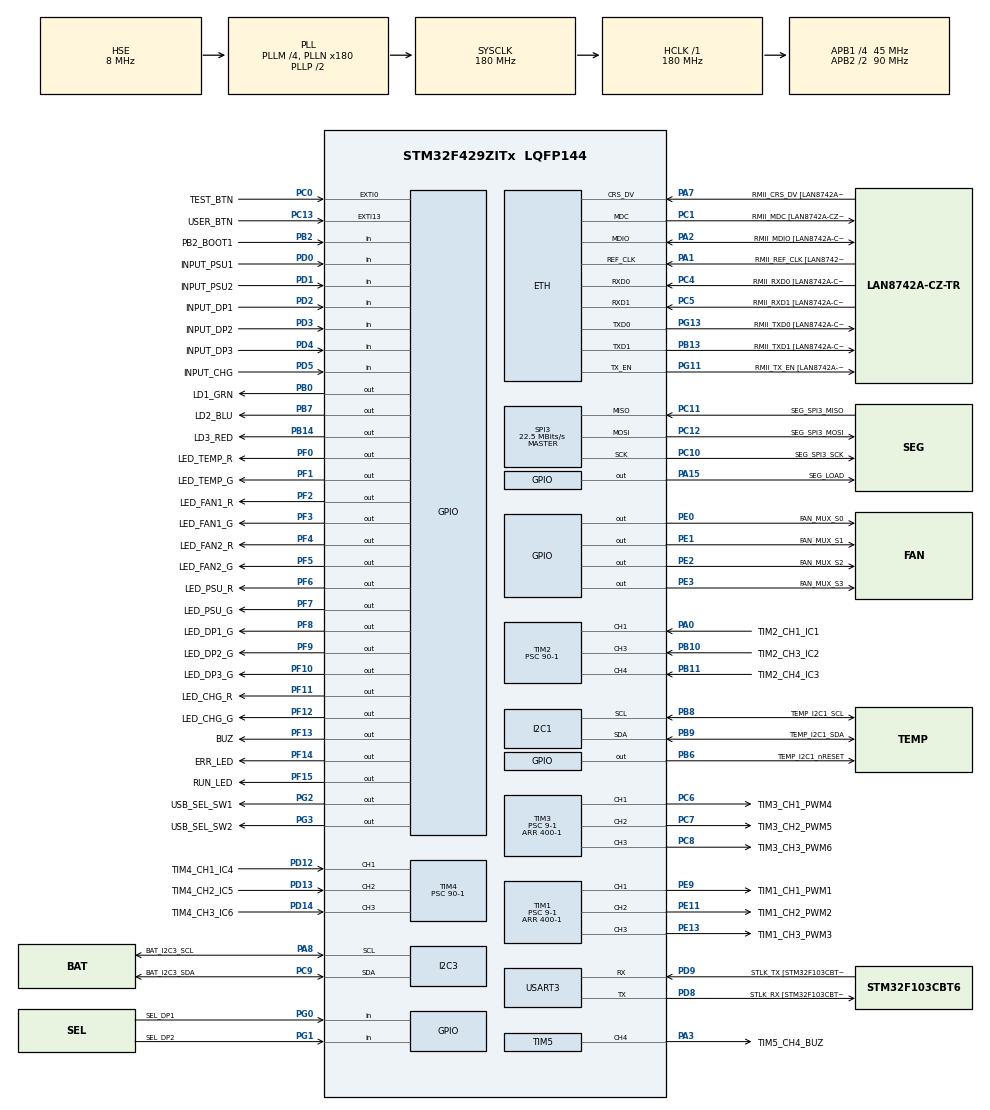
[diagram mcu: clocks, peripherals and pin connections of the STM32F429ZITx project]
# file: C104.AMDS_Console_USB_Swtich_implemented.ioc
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ETH.MediaInterface=HAL_ETH_RMII_MODE
LWIP.BSP.number=1
LWIP.GATEWAY_ADDRESS=192.168.050.001
LWIP.IP_ADDRESS=192.168.050.100
LWIP.LWIP_DHCP=0
LWIP.NETMASK_ADDRESS=255.255.255.000
LWIP.Version=v2.1.2_Cube
LWIP0.BSP.STBoard=false
LWIP0.BSP.api=BSP_COMPONENT_DRIVER
LWIP0.BSP.component=LAN8742
LWIP0.BSP.instance=LAN8742
LWIP0.BSP.name=Driver_PHY
LWIP0.BSP.semaphore=S_LAN8742
LWIP0.BSP.solution=LAN8742
Mcu.Family=STM32F4
Mcu.Name=STM32F429ZITx
Mcu.Package=LQFP144
NVIC.ETH_IRQn=true\:0\:0\:false\:false\:true\:true\:true\:true
NVIC.EXTI0_IRQn=true\:3\:0\:true\:false\:true\:true\:true\:true
NVIC.EXTI15_10_IRQn=true\:0\:0\:false\:false\:true\:true\:true\:true
NVIC.PriorityGroup=NVIC_PRIORITYGROUP_4
NVIC.TIM2_IRQn=true\:0\:0\:true\:false\:true\:true\:true\:true
NVIC.TIM4_IRQn=true\:0\:0\:true\:false\:true\:true\:true\:true
NVIC.TIM6_DAC_IRQn=true\:1\:0\:true\:false\:true\:true\:true\:true
NVIC.USART3_IRQn=true\:0\:0\:false\:false\:true\:true\:true\:true
PA0/WKUP.GPIO_Label=TIM2_CH1_IC1
PA0/WKUP.Signal=S_TIM2_CH1_ETR
PA1.GPIO_Label=RMII_REF_CLK [LAN8742A-CZ-TR_REFCLK0]
PA1.Mode=RMII
PA1.Signal=ETH_REF_CLK
PA13.GPIO_Label=SWDIO
PA13.Mode=Serial_Wire
PA13.Signal=SYS_JTMS-SWDIO
PA14.GPIO_Label=SWCLK
PA14.Mode=Serial_Wire
PA14.Signal=SYS_JTCK-SWCLK
PA15.GPIO_Label=SEG_LOAD
PA15.Signal=GPIO_Output
PA2.GPIO_Label=RMII_MDIO [LAN8742A-CZ-TR_MDIO]
PA2.Mode=RMII
PA2.Signal=ETH_MDIO
PA3.GPIO_Label=TIM5_CH4_BUZ
PA3.Signal=S_TIM5_CH4
PA7.GPIO_Label=RMII_CRS_DV [LAN8742A-CZ-TR_CRS_DV]
PA7.Mode=RMII
PA7.Signal=ETH_CRS_DV
PA8.GPIO_Label=BAT_I2C3_SCL
PA8.Mode=I2C
PA8.Signal=I2C3_SCL
PB0.GPIO_Label=LD1_GRN
PB0.Signal=GPIO_Output
PB10.GPIO_Label=TIM2_CH3_IC2
PB10.Signal=S_TIM2_CH3
PB11.GPIO_Label=TIM2_CH4_IC3
PB11.Signal=S_TIM2_CH4
PB13.GPIO_Label=RMII_TXD1 [LAN8742A-CZ-TR_TXD1]
PB13.Mode=RMII
PB13.Signal=ETH_TXD1
PB14.GPIO_Label=LD3_RED
PB14.Signal=GPIO_Output
PB2/BOOT1.GPIO_Label=PB2_BOOT1
PB2/BOOT1.Signal=GPIO_Input
PB6.GPIO_Label=TEMP_I2C1_nRESET
PB6.Signal=GPIO_Output
PB7.GPIO_Label=LD2_BLU
PB7.Signal=GPIO_Output
PB8.GPIO_Label=TEMP_I2C1_SCL
PB8.Mode=I2C
PB8.Signal=I2C1_SCL
PB9.GPIO_Label=TEMP_I2C1_SDA
PB9.Mode=I2C
PB9.Signal=I2C1_SDA
PC0.GPIO_Label=TEST_BTN
PC0.GPIO_ModeDefaultEXTI=GPIO_MODE_IT_FALLING
PC0.GPIO_PuPd=GPIO_NOPULL
PC0.Signal=GPXTI0
PC1.GPIO_Label=RMII_MDC [LAN8742A-CZ-TR_MDC]
PC1.Mode=RMII
PC1.Signal=ETH_MDC
PC10.GPIO_Label=SEG_SPI3_SCK
PC10.Mode=Full_Duplex_Master
PC10.Signal=SPI3_SCK
PC11.GPIO_Label=SEG_SPI3_MISO
PC11.Mode=Full_Duplex_Master
PC11.Signal=SPI3_MISO
PC12.GPIO_Label=SEG_SPI3_MOSI
PC12.Mode=Full_Duplex_Master
PC12.Signal=SPI3_MOSI
PC13.GPIO_Label=USER_BTN
PC13.GPIO_ModeDefaultEXTI=GPIO_MODE_IT_FALLING
PC13.GPIO_PuPd=GPIO_NOPULL
PC13.Signal=GPXTI13
PC14/OSC32_IN.Mode=LSE-External-Oscillator
PC14/OSC32_IN.Signal=RCC_OSC32_IN
PC15/OSC32_OUT.Mode=LSE-External-Oscillator
PC15/OSC32_OUT.Signal=RCC_OSC32_OUT
PC4.GPIO_Label=RMII_RXD0 [LAN8742A-CZ-TR_RXD0]
PC4.Mode=RMII
PC4.Signal=ETH_RXD0
PC5.GPIO_Label=RMII_RXD1 [LAN8742A-CZ-TR_RXD1]
PC5.Mode=RMII
PC5.Signal=ETH_RXD1
PC6.GPIO_Label=TIM3_CH1_PWM4
PC6.Signal=S_TIM3_CH1
PC7.GPIO_Label=TIM3_CH2_PWM5
PC7.Signal=S_TIM3_CH2
PC8.GPIO_Label=TIM3_CH3_PWM6
PC8.Signal=S_TIM3_CH3
PC9.GPIO_Label=BAT_I2C3_SDA
PC9.Mode=I2C
PC9.Signal=I2C3_SDA
PD0.GPIO_Label=INPUT_PSU1
PD0.GPIO_PuPd=GPIO_PULLUP
PD0.Signal=GPIO_Input
PD1.GPIO_Label=INPUT_PSU2
PD1.GPIO_PuPd=GPIO_PULLUP
PD1.Signal=GPIO_Input
PD12.GPIO_Label=TIM4_CH1_IC4
PD12.Signal=S_TIM4_CH1
PD13.GPIO_Label=TIM4_CH2_IC5
PD13.Signal=S_TIM4_CH2
PD14.GPIO_Label=TIM4_CH3_IC6
PD14.Signal=S_TIM4_CH3
PD2.GPIO_Label=INPUT_DP1
PD2.GPIO_PuPd=GPIO_PULLDOWN
PD2.Signal=GPIO_Input
PD3.GPIO_Label=INPUT_DP2
PD3.GPIO_PuPd=GPIO_PULLDOWN
PD3.Signal=GPIO_Input
PD4.GPIO_Label=INPUT_DP3
PD4.GPIO_PuPd=GPIO_PULLUP
PD4.Signal=GPIO_Input
PD5.GPIO_Label=INPUT_CHG
PD5.GPIO_PuPd=GPIO_PULLUP
PD5.Signal=GPIO_Input
PD8.GPIO_Label=STLK_RX [STM32F103CBT6_PA3]
PD8.Mode=Asynchronous
PD8.Signal=USART3_TX
PD9.GPIO_Label=STLK_TX [STM32F103CBT6_PA2]
PD9.Mode=Asynchronous
PD9.Signal=USART3_RX
PE0.GPIO_Label=FAN_MUX_S0
PE0.Signal=GPIO_Output
PE1.GPIO_Label=FAN_MUX_S1
PE1.Signal=GPIO_Output
PE11.GPIO_Label=TIM1_CH2_PWM2
PE11.Signal=S_TIM1_CH2
PE13.GPIO_Label=TIM1_CH3_PWM3
PE13.Signal=S_TIM1_CH3
PE2.GPIO_Label=FAN_MUX_S2
PE2.Signal=GPIO_Output
PE3.GPIO_Label=FAN_MUX_S3
PE3.Signal=GPIO_Output
PE9.GPIO_Label=TIM1_CH1_PWM1
PE9.Signal=S_TIM1_CH1
PF0.GPIO_Label=LED_TEMP_R
PF0.PinState=GPIO_PIN_SET
PF0.Signal=GPIO_Output
PF1.GPIO_Label=LED_TEMP_G
PF1.PinState=GPIO_PIN_SET
PF1.Signal=GPIO_Output
PF10.GPIO_Label=LED_DP3_G
PF10.PinState=GPIO_PIN_SET
PF10.Signal=GPIO_Output
PF11.GPIO_Label=LED_CHG_R
PF11.PinState=GPIO_PIN_SET
PF11.Signal=GPIO_Output
PF12.GPIO_Label=LED_CHG_G
PF12.PinState=GPIO_PIN_SET
PF12.Signal=GPIO_Output
PF13.GPIO_Label=BUZ
PF13.PinState=GPIO_PIN_SET
PF13.Signal=GPIO_Output
PF14.GPIO_Label=ERR_LED
PF14.Signal=GPIO_Output
PF15.GPIO_Label=RUN_LED
PF15.Signal=GPIO_Output
PF2.GPIO_Label=LED_FAN1_R
PF2.PinState=GPIO_PIN_SET
PF2.Signal=GPIO_Output
PF3.GPIO_Label=LED_FAN1_G
PF3.PinState=GPIO_PIN_SET
PF3.Signal=GPIO_Output
PF4.GPIO_Label=LED_FAN2_R
PF4.PinState=GPIO_PIN_SET
PF4.Signal=GPIO_Output
PF5.GPIO_Label=LED_FAN2_G
PF5.PinState=GPIO_PIN_SET
PF5.Signal=GPIO_Output
PF6.GPIO_Label=LED_PSU_R
PF6.PinState=GPIO_PIN_SET
PF6.Signal=GPIO_Output
PF7.GPIO_Label=LED_PSU_G
PF7.PinState=GPIO_PIN_SET
PF7.Signal=GPIO_Output
PF8.GPIO_Label=LED_DP1_G
PF8.PinState=GPIO_PIN_SET
PF8.Signal=GPIO_Output
PF9.GPIO_Label=LED_DP2_G
PF9.PinState=GPIO_PIN_SET
PF9.Signal=GPIO_Output
PG0.GPIO_Label=SEL_DP1
PG0.Signal=GPIO_Input
PG1.GPIO_Label=SEL_DP2
PG1.Signal=GPIO_Input
PG11.GPIO_Label=RMII_TX_EN [LAN8742A-CZ-TR_TXEN]
PG11.Mode=RMII
PG11.Signal=ETH_TX_EN
PG13.GPIO_Label=RMII_TXD0 [LAN8742A-CZ-TR_TXD0]
PG13.Mode=RMII
PG13.Signal=ETH_TXD0
PG2.GPIO_Label=USB_SEL_SW1
PG2.Signal=GPIO_Output
PG3.GPIO_Label=USB_SEL_SW2
PG3.Signal=GPIO_Output
PH0/OSC_IN.Mode=HSE-External-Oscillator
PH0/OSC_IN.Signal=RCC_OSC_IN
PH1/OSC_OUT.Mode=HSE-External-Oscillator
PH1/OSC_OUT.Signal=RCC_OSC_OUT
ProjectManager.HeapSize=0x200
ProjectManager.StackSize=0x400
ProjectManager.TargetToolchain=STM32CubeIDE
RCC.48MHZClocksFreq_Value=51428571.428571425
RCC.AHBFreq_Value=180000000
RCC.APB1CLKDivider=RCC_HCLK_DIV4
RCC.APB1Freq_Value=45000000
RCC.APB1TimFreq_Value=90000000
RCC.APB2CLKDivider=RCC_HCLK_DIV2
RCC.APB2Freq_Value=90000000
RCC.APB2TimFreq_Value=180000000
RCC.CortexFreq_Value=180000000
RCC.HCLKFreq_Value=180000000
RCC.HSE_VALUE=8000000
RCC.HSI_VALUE=16000000
RCC.PLLM=4
RCC.PLLMUL=RCC_PLL_MUL9
RCC.PLLN=180
RCC.PLLQ=7
RCC.PLLSourceVirtual=RCC_PLLSOURCE_HSE
RCC.PRESCALERUSB=RCC_USBCLKSOURCE_PLL_DIV1_5
RCC.SYSCLKFreq_VALUE=180000000
RCC.SYSCLKSource=RCC_SYSCLKSOURCE_PLLCLK
RCC.SYSCLKSourceVirtual=RCC_SYSCLKSOURCE_PLLCLK
RCC.USBFreq_Value=48000000
RCC.VCOOutputFreq_Value=360000000
SH.S_TIM1_CH1.0=TIM1_CH1,PWM Generation1 CH1
SH.S_TIM1_CH2.0=TIM1_CH2,PWM Generation2 CH2
SH.S_TIM1_CH3.0=TIM1_CH3,PWM Generation3 CH3
SH.S_TIM2_CH1_ETR.0=TIM2_CH1,Input_Capture1_from_TI1
SH.S_TIM2_CH3.0=TIM2_CH3,Input_Capture3_from_TI3
SH.S_TIM2_CH4.0=TIM2_CH4,Input_Capture4_from_TI4
SH.S_TIM3_CH1.0=TIM3_CH1,PWM Generation1 CH1
SH.S_TIM3_CH2.0=TIM3_CH2,PWM Generation2 CH2
SH.S_TIM3_CH3.0=TIM3_CH3,PWM Generation3 CH3
SH.S_TIM4_CH1.0=TIM4_CH1,Input_Capture1_from_TI1
SH.S_TIM4_CH2.0=TIM4_CH2,Input_Capture2_from_TI2
SH.S_TIM4_CH3.0=TIM4_CH3,Input_Capture3_from_TI3
SH.S_TIM5_CH4.0=TIM5_CH4,PWM Generation4 CH4
SPI3.BaudRatePrescaler=SPI_BAUDRATEPRESCALER_2
SPI3.CalculateBaudRate=22.5 MBits/s
SPI3.Direction=SPI_DIRECTION_2LINES
SPI3.Mode=SPI_MODE_MASTER
SPI3.VirtualType=VM_MASTER
TIM1.Channel-PWM\ Generation1\ CH1=TIM_CHANNEL_1
TIM1.Channel-PWM\ Generation2\ CH2=TIM_CHANNEL_2
TIM1.Channel-PWM\ Generation3\ CH3=TIM_CHANNEL_3
TIM1.Period=400-1
TIM1.Prescaler=9-1
TIM2.Channel-Input_Capture1_from_TI1=TIM_CHANNEL_1
TIM2.Channel-Input_Capture3_from_TI3=TIM_CHANNEL_3
TIM2.Channel-Input_Capture4_from_TI4=TIM_CHANNEL_4
TIM2.ICFilter_CH1=15
TIM2.ICFilter_CH3=15
TIM2.ICFilter_CH4=15
TIM2.Prescaler=90-1
TIM3.Channel-PWM\ Generation1\ CH1=TIM_CHANNEL_1
TIM3.Channel-PWM\ Generation2\ CH2=TIM_CHANNEL_2
TIM3.Channel-PWM\ Generation3\ CH3=TIM_CHANNEL_3
TIM3.Period=400-1
TIM3.Prescaler=9-1
TIM4.Channel-Input_Capture1_from_TI1=TIM_CHANNEL_1
TIM4.Channel-Input_Capture2_from_TI2=TIM_CHANNEL_2
TIM4.Channel-Input_Capture3_from_TI3=TIM_CHANNEL_3
TIM4.ICFilter_CH1=15
TIM4.ICFilter_CH2=15
TIM4.ICFilter_CH3=15
TIM4.Prescaler=90-1
TIM5.Channel-PWM\ Generation4\ CH4=TIM_CHANNEL_4
TIM5.Period=370
TIM5.Prescaler=90-1
TIM5.Pulse-PWM\ Generation4\ CH4=185
TIM6.Period=10000-1
TIM6.Prescaler=900-1
USART3.VirtualMode=VM_ASYNC
VP_LWIP_VS_Enabled.Mode=Enabled
VP_TIM6_VS_ClockSourceINT.Mode=Enable_Timer
board=NUCLEO-F429ZI

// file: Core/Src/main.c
/* USER CODE BEGIN Header */
/**
  ******************************************************************************
  * @file           : main.c
  * @brief          : Main program body
  ******************************************************************************
  * @attention
  *
  * Copyright (c) 2024 STMicroelectronics.
  * All rights reserved.
  *
  * This software is licensed under terms that can be found in the LICENSE file
  * in the root directory of this software component.
  * If no LICENSE file comes with this software, it is provided AS-IS.
  *
  ******************************************************************************
  */
/* USER CODE END Header */
#include "main.h"
#include "i2c.h"
#include "lwip.h"
#include "spi.h"
#include "tim.h"
#include "usart.h"
#include "gpio.h"

/* USER CODE BEGIN Includes */
#include <stdlib.h>
#include <udp_server.h>
#include "ring_buffer.h"
#include "pid.h"
#include "ema.h"
#include "user_timer.h"
#include "fan_control.h"
#include "debug_uart.h"
#include "hih8131.h"
#include "bq34z100.h"
#include "process.h"
#include "max7219.h"
#include "display.h"
#include "udp_protocol.h"
#include "send.h"
#include "debug_uart.h"
#include "buzzer.h"

/* USER CODE END Includes */

/* USER CODE BEGIN PV */
uint8_t timer_interrupt_100ms_done = 0;
uint8_t timer_interrupt_1sec_done = 0;
uint8_t key_pressed = 0;
uint8_t keyno = 0;

//----------------------
//RingBuffer rxBuffer;

/* USER CODE END PV */

void SystemClock_Config(void);
/* USER CODE BEGIN PFP */
int _write(int file, char* p, int len)
{
	HAL_UART_Transmit(&huart3, (const uint8_t *)p, len, 10);
	return len;
}

/* USER CODE END PFP */

/* USER CODE BEGIN 0 */
uint32_t stamp_100ms = 0;
uint32_t stamp_1sec = 0;
int8_t cmd_received = 1;
//uint8_t command[50] = {0, };

//UDP Server
extern struct netif gnetif;
extern ip4_addr_t ipaddr;

/* USER CODE END 0 */

int main(void)
{

  /* MCU Configuration--------------------------------------------------------*/

  /* Reset of all peripherals, Initializes the Flash interface and the Systick. */
  HAL_Init();

  /* Configure the system clock */
  SystemClock_Config();

  /* Initialize all configured peripherals */
  MX_GPIO_Init();
  MX_USART3_UART_Init();
  MX_I2C1_Init();
  MX_TIM1_Init();
  MX_TIM2_Init();
  MX_TIM3_Init();
  MX_TIM4_Init();
  MX_LWIP_Init();
  MX_TIM6_Init();
  MX_I2C3_Init();
  MX_SPI3_Init();
  MX_TIM5_Init();
  /* USER CODE BEGIN 2 */
  uTimer_Init();
  LED_Init();
  MAX7219_Init();
  Buzzer_Init();

  DBG_Uart_Init();
  HAL_UART_Receive_IT(&huart3, (uint8_t *)&rxBuffer.buffer[rxBuffer.head], 1);

  FAN_Init();
  HMTP_Init();
  UDP_Protocol_Init();

  configure_mac_filter();
  udpServer_init();
  Process_Init();

  HAL_TIM_Base_Start_IT(&htim6);

 printf("\nC104.AMDS_Console_TempStatus_with_avg_value\n");

 //Send_Portable_Status()
 setbuf(stdout,NULL);
  /* USER CODE END 2 */

  /* Infinite loop */
  /* USER CODE BEGIN WHILE */
 HAL_GPIO_WritePin(LED_DP1_G_GPIO_Port, LED_DP1_G_Pin, GPIO_PIN_SET);
 HAL_GPIO_WritePin(LED_DP2_G_GPIO_Port, LED_DP2_G_Pin, GPIO_PIN_SET);
 HAL_GPIO_WritePin(LED_DP3_G_GPIO_Port, LED_DP3_G_Pin, GPIO_PIN_SET);

 uint8_t toggle = 0;
  while (1)
  {
	//HAL_GPIO_WritePin(LED_DP1_G_GPIO_Port, LED_DP1_G_Pin, GPIO_PIN_RESET);
    ethernetif_input(&gnetif);
    sys_check_timeouts();

    HAL_GPIO_WritePin(LED_DP1_G_GPIO_Port, LED_DP1_G_Pin, GPIO_PIN_SET);
    HAL_GPIO_WritePin(LED_DP2_G_GPIO_Port, LED_DP2_G_Pin, GPIO_PIN_SET);
    HAL_GPIO_WritePin(LED_DP3_G_GPIO_Port, LED_DP3_G_Pin, GPIO_PIN_SET);

    Process_Console_Status();

    if(key_pressed == 1)
    {
      toggle = !toggle;

      if(uTimer_CheckTimeOut((uint8_t)uTimerDebounce) == TRUE)
      {
        //if(toggle==1) Buzzer_On();
        //else Buzzer_Off();

        //Send_Portable_Status();
        key_pressed = 0;
      }
    }

    /* USER CODE END WHILE */

  }
}

void SystemClock_Config(void)
{
  RCC_OscInitTypeDef RCC_OscInitStruct = {0};
  RCC_ClkInitTypeDef RCC_ClkInitStruct = {0};

  /** Configure the main internal regulator output voltage
  */
  __HAL_RCC_PWR_CLK_ENABLE();
  __HAL_PWR_VOLTAGESCALING_CONFIG(PWR_REGULATOR_VOLTAGE_SCALE1);

  /** Initializes the RCC Oscillators according to the specified parameters
  * in the RCC_OscInitTypeDef structure.
  */
  RCC_OscInitStruct.OscillatorType = RCC_OSCILLATORTYPE_HSE;
  RCC_OscInitStruct.HSEState = RCC_HSE_ON;
  RCC_OscInitStruct.PLL.PLLState = RCC_PLL_ON;
  RCC_OscInitStruct.PLL.PLLSource = RCC_PLLSOURCE_HSE;
  RCC_OscInitStruct.PLL.PLLM = 4;
  RCC_OscInitStruct.PLL.PLLN = 180;
  RCC_OscInitStruct.PLL.PLLP = RCC_PLLP_DIV2;
  RCC_OscInitStruct.PLL.PLLQ = 7;
  if (HAL_RCC_OscConfig(&RCC_OscInitStruct) != HAL_OK)
  {
    Error_Handler();
  }

  /** Activate the Over-Drive mode
  */
  if (HAL_PWREx_EnableOverDrive() != HAL_OK)
  {
    Error_Handler();
  }

  /** Initializes the CPU, AHB and APB buses clocks
  */
  RCC_ClkInitStruct.ClockType = RCC_CLOCKTYPE_HCLK|RCC_CLOCKTYPE_SYSCLK
                              |RCC_CLOCKTYPE_PCLK1|RCC_CLOCKTYPE_PCLK2;
  RCC_ClkInitStruct.SYSCLKSource = RCC_SYSCLKSOURCE_PLLCLK;
  RCC_ClkInitStruct.AHBCLKDivider = RCC_SYSCLK_DIV1;
  RCC_ClkInitStruct.APB1CLKDivider = RCC_HCLK_DIV4;
  RCC_ClkInitStruct.APB2CLKDivider = RCC_HCLK_DIV2;

  if (HAL_RCC_ClockConfig(&RCC_ClkInitStruct, FLASH_LATENCY_5) != HAL_OK)
  {
    Error_Handler();
  }
}

/* USER CODE BEGIN 4 */
void HAL_TIM_PeriodElapsedCallback(TIM_HandleTypeDef *htim)
{
	static uint32_t last_blink_tick = 0;

	if(htim->Instance == TIM6)
	{
		if (HAL_GetTick() - last_blink_tick >= 500) {
			last_blink_tick = HAL_GetTick();

			HAL_GPIO_TogglePin(RUN_LED_GPIO_Port, RUN_LED_Pin);
			HAL_GPIO_TogglePin(LD3_RED_GPIO_Port, LD3_RED_Pin);
			HAL_GPIO_TogglePin(LD2_BLU_GPIO_Port, LD2_BLU_Pin);

			HAL_GPIO_TogglePin(LED_DP1_G_GPIO_Port, LED_DP1_G_Pin);
			HAL_GPIO_TogglePin(LED_DP2_G_GPIO_Port, LED_DP2_G_Pin);
			HAL_GPIO_TogglePin(LED_DP3_G_GPIO_Port, LED_DP3_G_Pin);

			//HAL_GPIO_TogglePin(LED_TEMP_R_GPIO_Port, LED_TEMP_R_Pin);
			//HAL_GPIO_TogglePin(LED_TEMP_G_GPIO_Port, LED_TEMP_G_Pin);
			//HAL_GPIO_TogglePin(LED_TEMP_R_GPIO_Port, LED_TEMP_R_Pin);
			//HAL_GPIO_TogglePin(LED_TEMP_G_GPIO_Port, LED_TEMP_G_Pin);

			//HAL_GPIO_TogglePin(LED_PSU_R_GPIO_Port, LED_PSU_R_Pin);
			//HAL_GPIO_TogglePin(LED_PSU_G_GPIO_Port, LED_PSU_G_Pin);

			//HAL_GPIO_TogglePin(LED_FAN1_R_GPIO_Port, LED_FAN1_R_Pin);
			//HAL_GPIO_TogglePin(LED_FAN1_G_GPIO_Port, LED_FAN1_G_Pin);

			//HAL_GPIO_TogglePin(LED_FAN2_R_GPIO_Port, LED_FAN2_R_Pin);
			//HAL_GPIO_TogglePin(LED_FAN2_G_GPIO_Port, LED_FAN2_G_Pin);
		}
	}
}

void HAL_GPIO_EXTI_Callback(uint16_t GPIO_Pin)
{
    if(GPIO_Pin == USER_BTN_Pin)
  {
    HAL_NVIC_DisableIRQ(EXTI15_10_IRQn);
    //---------------------------------------------------------
    if(key_pressed == 0)
    {
      printf("key_pressed !\n");
      key_pressed = 1;
    }

    //---------------------------------------------------------
    HAL_NVIC_EnableIRQ(EXTI15_10_IRQn);

  }//USER_BTN_Pin

  if(GPIO_Pin == TEST_BTN_Pin)
  {
    HAL_NVIC_DisableIRQ(EXTI0_IRQn);
    //---------------------------------------------------------
    if(key_pressed == 0)
    {
      uTimer_Regist(((uint8_t)uTimerDebounce), KEY_TIMERCNT);
      keyno = fan_step;

      if(keyno <5 ) {
        keyno++;
      }
      if (keyno > 4) {
        keyno = 0;
      }
      fan_step = keyno;

      key_pressed = 1;

      printf("STEP : %d \n", keyno);
    }
    //---------------------------------------------------------
    HAL_NVIC_EnableIRQ(EXTI0_IRQn);

  }//TEST_BTN_Pin
}

/* USER CODE END 4 */

void Error_Handler(void)
{
  __disable_irq();
  while (1)
  {
  }
}
